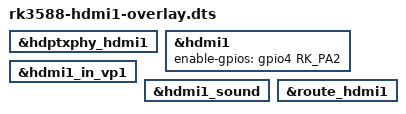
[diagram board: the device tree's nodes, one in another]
/dts-v1/;
/plugin/;

#include <dt-bindings/gpio/gpio.h>
#include <dt-bindings/pinctrl/rockchip.h>
#include <dt-bindings/display/drm_mipi_dsi.h>
#include <dt-bindings/interrupt-controller/irq.h>

/ {
    fragment@0 {
        target = <&hdptxphy_hdmi1>;
        __overlay__ {
            status = "okay";
        };
    };
    fragment@1 {
        target = <&hdmi1>;
        __overlay__ {
            enable-gpios = <&gpio4 RK_PA2 GPIO_ACTIVE_HIGH>;
            status = "okay";
        };
    };
    fragment@2 {
        target = <&hdmi1_in_vp1>;
        __overlay__ {
            status = "okay";
        };
    };
    fragment@3 {
        target = <&hdmi1_sound>;
        __overlay__ {
            status = "okay";
        };
    };
    fragment@4 {
        target = <&route_hdmi1>;
        __overlay__ {
            status = "okay";
        };
    };
};
